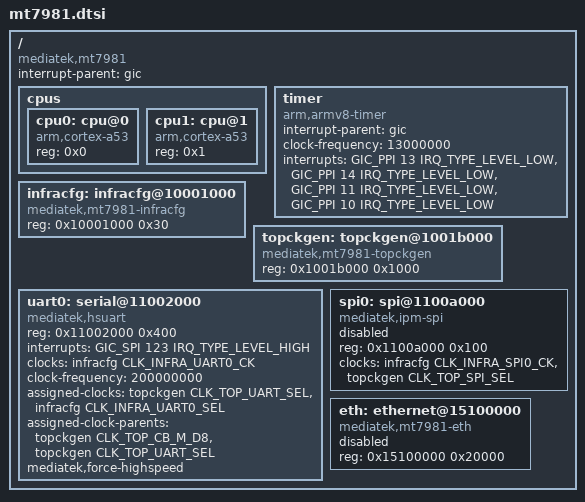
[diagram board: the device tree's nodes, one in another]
// SPDX-License-Identifier: GPL-2.0
/*
 * SL3000 V2 Clock Alignment Patch
 * Fixes: 576000 Baudrate offset (200MHz vs 40MHz)
 */

#include <dt-bindings/interrupt-controller/irq.h>
#include <dt-bindings/interrupt-controller/arm-gic.h>
#include <dt-bindings/phy/phy.h>
#include <dt-bindings/clock/mt7981-clk.h>
#include <dt-bindings/reset/mt7629-reset.h>
#include <dt-bindings/pinctrl/mt65xx.h>

/ {
	compatible = "mediatek,mt7981";
	interrupt-parent = <&gic>;
	#address-cells = <1>;
	#size-cells = <1>;

	cpus {
		#address-cells = <1>;
		#size-cells = <0>;
		cpu0: cpu@0 {
			device_type = "cpu";
			compatible = "arm,cortex-a53";
			reg = <0x0>;
		};
		cpu1: cpu@1 {
			device_type = "cpu";
			compatible = "arm,cortex-a53";
			reg = <0x1>;
		};
	};

	/* 修正全局定时器基准 */
	timer {
		compatible = "arm,armv8-timer";
		interrupt-parent = <&gic>;
		clock-frequency = <13000000>;
		interrupts = <GIC_PPI 13 IRQ_TYPE_LEVEL_LOW>,
			     <GIC_PPI 14 IRQ_TYPE_LEVEL_LOW>,
			     <GIC_PPI 11 IRQ_TYPE_LEVEL_LOW>,
			     <GIC_PPI 10 IRQ_TYPE_LEVEL_LOW>;
	};

	infracfg: infracfg@10001000 {
		compatible = "mediatek,mt7981-infracfg";
		reg = <0x10001000 0x30>;
		#clock-cells = <1>;
		bootph-all;
	};

	topckgen: topckgen@1001b000 {
		compatible = "mediatek,mt7981-topckgen";
		reg = <0x1001b000 0x1000>;
		#clock-cells = <1>;
		bootph-all;
	};

	/* 核心修复点：UART0 物理时钟锁定 */
	uart0: serial@11002000 {
		compatible = "mediatek,hsuart";
		reg = <0x11002000 0x400>;
		interrupts = <GIC_SPI 123 IRQ_TYPE_LEVEL_HIGH>;
		clocks = <&infracfg CLK_INFRA_UART0_CK>;
		/* 物理同步：强制声明时钟源为 200MHz */
		clock-frequency = <200000000>; 
		assigned-clocks = <&topckgen CLK_TOP_UART_SEL>,
				  <&infracfg CLK_INFRA_UART0_SEL>;
		/* 将父时钟从 40M 切换到 200M (Bus Clock) */
		assigned-clock-parents = <&topckgen CLK_TOP_CB_M_D8>, 
					 <&topckgen CLK_TOP_UART_SEL>;
		mediatek,force-highspeed;
		status = "okay";
		bootph-all;
	};

	/* 保持其他外设定义不变... */
	spi0: spi@1100a000 {
		compatible = "mediatek,ipm-spi";
		reg = <0x1100a000 0x100>;
		clocks = <&infracfg CLK_INFRA_SPI0_CK>,
			 <&topckgen CLK_TOP_SPI_SEL>;
		status = "disabled";
	};

	eth: ethernet@15100000 {
		compatible = "mediatek,mt7981-eth", "syscon";
		reg = <0x15100000 0x20000>;
		#address-cells = <1>;
		#size-cells = <0>;
		status = "disabled";
	};
};
